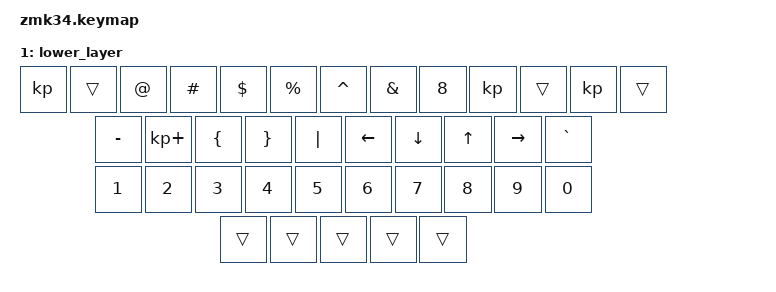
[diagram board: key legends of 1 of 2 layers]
/*

Copyright (c) 2020 The ZMK Contributors

SPDX-License-Identifier: MIT
*/
#include <behaviors.dtsi>
#include <dt-bindings/zmk/keys.h>
#include <dt-bindings/zmk/rgb.h>
#include <dt-bindings/zmk/bt.h>
  keymap {
    compatible = "zmk,keymap";
    default_layer {
      // -------------------------------------------------------------------------------------
     // | ESC | P | Y | F | G | C | H | L | mo1 | BSPC |
     // | A   | O | E | U | I | D | R | T | N   | S  |
     // | Q   | J | K | X | B | M | W | V | Z |
     // | LSHFT | LCTRL | ENT | SPC | ALT |
     bindings = <
      &kp ESC &kp P &kp Y &kp F &kp G &kp C &kp H &kp L &mo 1 &kp BSPC
      &kp A &kp O &kp E &kp U &kp I &kp D &kp R &kp T &kp N &kp S
      &kp Q &kp J &kp K &kp X &kp B &kp M &kp W &kp V &kp Z
      &kp LSHFT &kp LCTRL &kp RET &kp SPACE &kp RALT;
  };
    lower_layer {
    // ----------------------------------------------------------------------------------
    // | ! | @ | # | $ | % | ^ | & | * | ( | ) |
    // | _ | + | { | } | "|" | LFT | DWN | UP | RGT | ` |
    // | 1 | 2 | 3 | 4 | 5 | 6 | 7 | 8 | 9 | 0 |
    // | LSHFT | LCTRL | ENT | SPC | ALT |
    bindings = <
      &kp &trans &kp AT &kp HASH &kp DLLR &kp PRCNT &kp CARET &kp AMPS &kp N8 &kp &trans &kp &trans
      &kp MINUS &kp KP_PLUS &kp LBRC &kp RBRC &kp PIPE &kp LEFT &kp DOWN &kp UP &kp RIGHT &kp GRAVE
      &kp N1 &kp N2 &kp N3 &kp N4 &kp N5 &kp N6 &kp N7 &kp N8 &kp N9 &kp N0
      &trans &trans &trans &trans &trans;
  };
};
